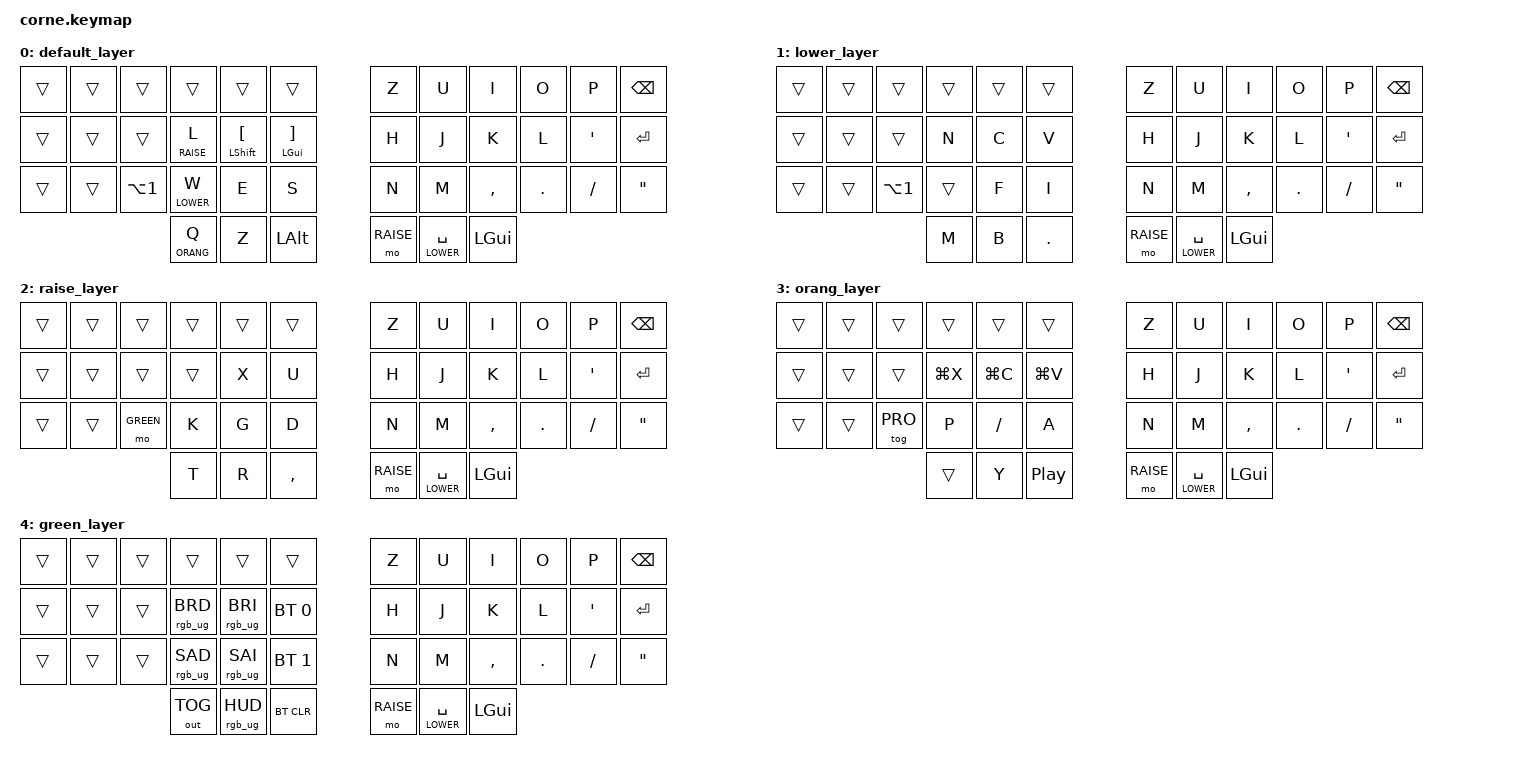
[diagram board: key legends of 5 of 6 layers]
#include <behaviors.dtsi>
#include <dt-bindings/zmk/keys.h>
#include <dt-bindings/zmk/bt.h>
#include <dt-bindings/zmk/rgb.h>
#include <dt-bindings/zmk/ext_power.h>
#include <dt-bindings/zmk/outputs.h>

#define DEFAULT 0
#define LOWER   1
#define RAISE   2
#define ORANG   3
#define GREEN   4
#define PRO     5

&left_encoder { resolution = <2>; };
// &left1_encoder { resolution = <2>; };
// &right_encoder { resolution = <1>; };

&mt {
    tapping-term-ms = <135>;
};

&lt {
    tapping-term-ms = <135>;
};

&spi1 {
	compatible = "nordic,nrf-spim";
	status = "okay";
	mosi-pin = <6>;
	// Unused pins, needed for SPI definition, but not used by the ws2812 driver itself.
	sck-pin = <5>;
	miso-pin = <7>;

	led_strip: ws2812@0 {
		compatible = "worldsemi,ws2812-spi";
		label = "WS2812";

		/* SPI */
		reg = <0>; /* ignored, but necessary for SPI bindings */
		spi-max-frequency = <4000000>;

		/* WS2812 */
		chain-length = <4>; /* arbitrary; change at will */
		spi-one-frame = <0x70>;
		spi-zero-frame = <0x40>;
	};
};

/ {
	chosen {
		zmk,underglow = &led_strip;
	};
};


/ {
        keymap {
                compatible = "zmk,keymap";

                default_layer {
// -----------------------------------------------------------------------------------------
// |  TAB |  Q  |  W  |  E  |  R  |  T  |   |  Y  |  U   |  I  |  O  |  P  | BKSP |
// | CTRL |  A  |  S  |  D  |  F  |  G  |   |  H  |  J   |  K  |  L  |  ;  |  '   |
// | SHFT |  Z  |  X  |  C  |  V  |  B  |   |  N  |  M   |  ,  |  .  |  /  | SHFT |
//                    | GUI | LWR | SPC |   | ENT | RSE  | ALT |
                        bindings = <
   &trans &trans &trans       &trans    &trans   &trans                                  &kp Z &kp U  &kp I    &kp O   &kp P    &kp BKSP
   &trans &trans &trans       &lt RAISE L &mt LSHIFT LBKT &mt LGUI RBKT                  &kp H &kp J  &kp K    &kp L   &kp APOS &kp RET
   &trans &trans &kp LA(N1)   &lt LOWER W &kp E &kp S                                    &kp N &kp M  &kp CMMA &kp DOT &kp FSLH &kp DQT
                              &lt ORANG Q &kp Z &kp LALT                                 &mo RAISE &lt LOWER SPACE &kp LGUI
                        >;
                        sensor-bindings = <&inc_dec_kp N5 N6 >;
                };
                lower_layer {
// -----------------------------------------------------------------------------------------
// |  ESC |  1  |  2  |  3  |  4  |  5  |   |  6  |  7  |  8  |  9  |  0  | BKSP |
// | BTCLR| BT1 | BT2 | BT3 | BT4 | BT5 |   | LFT | DWN |  UP | RGT |     |      |
// | SHFT |     |     |     |     |     |   |     |     |     |     |     |      |
//                    | GUI |     | SPC |   | ENT |     | ALT |
                        bindings = <
   &trans &trans &trans     &trans &trans &trans                   &kp Z &kp U  &kp I    &kp O   &kp P    &kp BKSP
   &trans &trans &trans     &kp N  &kp C  &kp V                 &kp H &kp J  &kp K    &kp L   &kp APOS &kp RET
   &trans &trans &kp LA(N1) &trans &kp F  &kp I                            &kp N &kp M  &kp CMMA &kp DOT &kp FSLH &kp DQT
                            &kp M  &kp B  &kp PERIOD                       &mo RAISE &lt LOWER SPACE &kp LGUI
                        >;
                        sensor-bindings = <&inc_dec_kp LC(LBKT) LC(RBKT)>;
                };
                raise_layer {
// -----------------------------------------------------------------------------------------
// |  ESC |  !  |  @  |  #  |  $  |  %  |   |  ^  |  &  |  *  |  (  |  )  | BKSP |
// | CTRL |     |     |     |     |     |   |  -  |  =  |  {  |  }  | "|" |  `   |
// | SHFT |     |     |     |     |     |   |  _  |  +  |  [  |  ]  |  \  |  ~   | // TODO: Fix this row when &mkp is committed
//                    | GUI |     | SPC |   | ENT |     | ALT |
                        bindings = <
   &trans &trans &trans     &trans  &trans &trans                 &kp Z &kp U  &kp I    &kp O   &kp P    &kp BKSP
   &trans &trans &trans     &trans  &kp X  &kp U                  &kp H &kp J  &kp K    &kp L   &kp APOS &kp RET
   &trans &trans &mo GREEN  &kp K   &kp G  &kp D                            &kp N &kp M  &kp CMMA &kp DOT &kp FSLH &kp DQT
                            &kp T   &kp R  &kp COMMA                      &mo RAISE &lt LOWER SPACE &kp LGUI
                        >;
                        sensor-bindings = <&inc_dec_kp LC(LBKT) LC(RBKT)>;
                };
                orang_layer {
// -----------------------------------------------------------------------------------------
// |  ESC |  !  |  @  |  #  |  $  |  %  |   |  ^  |  &  |  *  |  (  |  )  | BKSP |
// | CTRL |     |     |     |     |     |   |  -  |  =  |  {  |  }  | "|" |  `   |
// | SHFT |     |     |     |     |     |   |  _  |  +  |  [  |  ]  |  \  |  ~   | // TODO: Fix this row when &mkp is committed
//                    | GUI |     | SPC |   | ENT |     | ALT |
                        bindings = <
   &trans &trans &trans    &trans    &trans    &trans                   &kp Z &kp U  &kp I    &kp O   &kp P    &kp BKSP
   &trans &trans &trans    &kp LG(X) &kp LG(C) &kp LG(V)                  &kp H &kp J  &kp K    &kp L   &kp APOS &kp RET
   &trans &trans &tog PRO  &kp P     &kp SLASH &kp A                           &kp N &kp M  &kp CMMA &kp DOT &kp FSLH &kp DQT
                           &trans    &kp Y     &kp C_PLAY_PAUSE                      &mo RAISE &lt LOWER SPACE &kp LGUI
                        >;
                        sensor-bindings = <&inc_dec_kp C_VOL_DN C_VOL_UP>;
                };
                green_layer {
// -----------------------------------------------------------------------------------------
// |  ESC |  !  |  @  |  #  |  $  |  %  |   |  ^  |  &  |  *  |  (  |  )  | BKSP |
// | CTRL |     |     |     |     |     |   |  -  |  =  |  {  |  }  | "|" |  `   |
// | SHFT |     |     |     |     |     |   |  _  |  +  |  [  |  ]  |  \  |  ~   | // TODO: Fix this row when &mkp is committed
//                    | GUI |     | SPC |   | ENT |     | ALT |
                        bindings = <
   &trans &trans &trans     &trans          &trans          &trans                   &kp Z &kp U  &kp I    &kp O   &kp P    &kp BKSP
   &trans &trans &trans     &rgb_ug RGB_BRD &rgb_ug RGB_BRI &bt BT_SEL 0                  &kp H &kp J  &kp K    &kp L   &kp APOS &kp RET
   &trans &trans &trans     &rgb_ug RGB_SAD &rgb_ug RGB_SAI &bt BT_SEL 1                            &kp N &kp M  &kp CMMA &kp DOT &kp FSLH &kp DQT
                                      &out OUT_TOG &rgb_ug RGB_HUD &bt BT_CLR                      &mo RAISE &lt LOWER SPACE &kp LGUI
                        >;
                        sensor-bindings = <&inc_dec_kp N5 N6>;
                };
                pro_layer {
// -----------------------------------------------------------------------------------------
// |  ESC |  1  |  2  |  3  |  4  |  5  |   |  6  |  7  |  8  |  9  |  0  | BKSP |
// | BTCLR| BT1 | BT2 | BT3 | BT4 | BT5 |   | LFT | DWN |  UP | RGT |     |      |
// | SHFT |     |     |     |     |     |   |     |     |     |     |     |      |
//                    | GUI |     | SPC |   | ENT |     | ALT |
                        bindings = <
   &trans &trans &trans     &trans    &trans   &trans                   &kp Z &kp U  &kp I    &kp O   &kp P    &kp BKSP
   &trans &trans &trans     &kp L     &kp LBKT &kp RBKT                 &kp H &kp J  &kp K    &kp L   &kp APOS &kp RET
   &trans &trans &kp &trans &kp B     &kp E    &kp S                            &kp N &kp M  &kp CMMA &kp DOT &kp FSLH &kp DQT
                            &kp LG(K) &kp V    &kp LALT                       &mo RAISE &lt LOWER SPACE &kp LGUI
                        >;
                        sensor-bindings = <&inc_dec_kp LG(LBKT) LG(RBKT)>;
                };
        };
};


